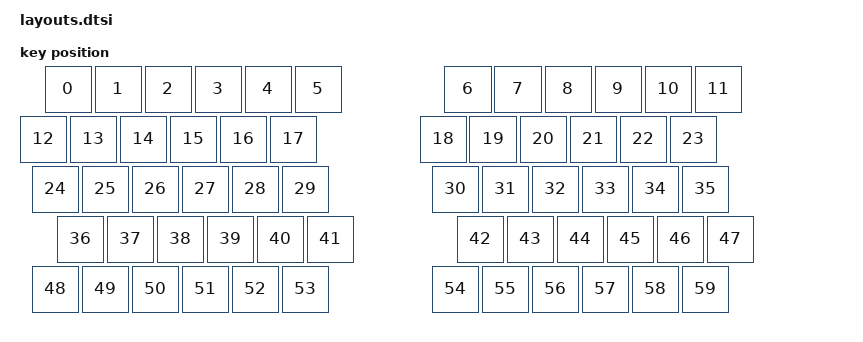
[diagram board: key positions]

#include <physical_layouts.dtsi>
/ {
    physical_layout0: physical_layout0 {
        compatible = "zmk,physical-layout";
        display-name = "Layout";
        keys
            = <&key_physical_attrs 100 100 0 0 0 0 0>
			,<&key_physical_attrs 100 100 100 0 0 0 0>
			,<&key_physical_attrs 100 100 200 0 0 0 0>
			,<&key_physical_attrs 100 100 300 0 0 0 0>
			,<&key_physical_attrs 100 100 400 0 0 0 0>
			,<&key_physical_attrs 100 100 500 0 0 0 0>
			,<&key_physical_attrs 100 100 800 0 0 0 0>
			,<&key_physical_attrs 100 100 900 0 0 0 0>
			,<&key_physical_attrs 100 100 1000 0 0 0 0>
			,<&key_physical_attrs 100 100 1100 0 0 0 0>
			,<&key_physical_attrs 100 100 1200 0 0 0 0>
			,<&key_physical_attrs 100 100 1300 0 0 0 0>
			,<&key_physical_attrs 100 100 (-50) 100 0 0 0>
			,<&key_physical_attrs 100 100 50 100 0 0 0>
			,<&key_physical_attrs 100 100 150 100 0 0 0>
			,<&key_physical_attrs 100 100 250 100 0 0 0>
			,<&key_physical_attrs 100 100 350 100 0 0 0>
			,<&key_physical_attrs 100 100 450 100 0 0 0>
			,<&key_physical_attrs 100 100 750 100 0 0 0>
			,<&key_physical_attrs 100 100 850 100 0 0 0>
			,<&key_physical_attrs 100 100 950 100 0 0 0>
			,<&key_physical_attrs 100 100 1050 100 0 0 0>
			,<&key_physical_attrs 100 100 1150 100 0 0 0>
			,<&key_physical_attrs 100 100 1250 100 0 0 0>
			,<&key_physical_attrs 100 100 (-25) 200 0 0 0>
			,<&key_physical_attrs 100 100 75 200 0 0 0>
			,<&key_physical_attrs 100 100 175 200 0 0 0>
			,<&key_physical_attrs 100 100 275 200 0 0 0>
			,<&key_physical_attrs 100 100 375 200 0 0 0>
			,<&key_physical_attrs 100 100 475 200 0 0 0>
			,<&key_physical_attrs 100 100 775 200 0 0 0>
			,<&key_physical_attrs 100 100 875 200 0 0 0>
			,<&key_physical_attrs 100 100 975 200 0 0 0>
			,<&key_physical_attrs 100 100 1075 200 0 0 0>
			,<&key_physical_attrs 100 100 1175 200 0 0 0>
			,<&key_physical_attrs 100 100 1275 200 0 0 0>
			,<&key_physical_attrs 100 100 25 300 0 0 0>
			,<&key_physical_attrs 100 100 125 300 0 0 0>
			,<&key_physical_attrs 100 100 225 300 0 0 0>
			,<&key_physical_attrs 100 100 325 300 0 0 0>
			,<&key_physical_attrs 100 100 425 300 0 0 0>
			,<&key_physical_attrs 100 100 525 300 0 0 0>
			,<&key_physical_attrs 100 100 825 300 0 0 0>
			,<&key_physical_attrs 100 100 925 300 0 0 0>
			,<&key_physical_attrs 100 100 1025 300 0 0 0>
			,<&key_physical_attrs 100 100 1125 300 0 0 0>
			,<&key_physical_attrs 100 100 1225 300 0 0 0>
			,<&key_physical_attrs 100 100 1325 300 0 0 0>
			,<&key_physical_attrs 100 100 (-25) 400 0 0 0>
			,<&key_physical_attrs 100 100 75 400 0 0 0>
			,<&key_physical_attrs 100 100 175 400 0 0 0>
			,<&key_physical_attrs 100 100 275 400 0 0 0>
			,<&key_physical_attrs 100 100 375 400 0 0 0>
			,<&key_physical_attrs 100 100 475 400 0 0 0>
			,<&key_physical_attrs 100 100 775 400 0 0 0>
			,<&key_physical_attrs 100 100 875 400 0 0 0>
			,<&key_physical_attrs 100 100 975 400 0 0 0>
			,<&key_physical_attrs 100 100 1075 400 0 0 0>
			,<&key_physical_attrs 100 100 1175 400 0 0 0>
			,<&key_physical_attrs 100 100 1275 400 0 0 0>
            ;
    };
};
    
